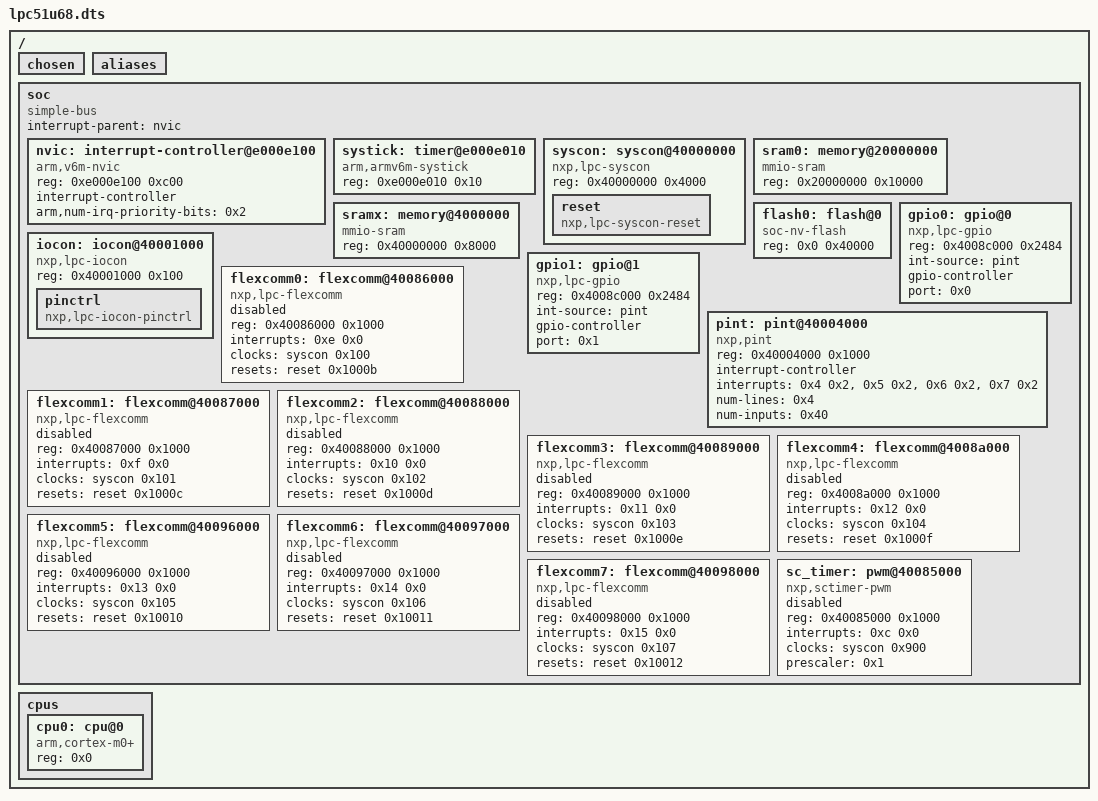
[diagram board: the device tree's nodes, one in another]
/dts-v1/;

/ {
	#address-cells = < 0x1 >;
	#size-cells = < 0x1 >;
	chosen {
	};
	aliases {
	};
	soc {
		#address-cells = < 0x1 >;
		#size-cells = < 0x1 >;
		compatible = "simple-bus";
		interrupt-parent = < &nvic >;
		ranges;
		nvic: interrupt-controller@e000e100 {
			#address-cells = < 0x1 >;
			compatible = "arm,v6m-nvic";
			reg = < 0xe000e100 0xc00 >;
			interrupt-controller;
			#interrupt-cells = < 0x2 >;
			arm,num-irq-priority-bits = < 0x2 >;
			phandle = < 0x1 >;
		};
		systick: timer@e000e010 {
			compatible = "arm,armv6m-systick";
			reg = < 0xe000e010 0x10 >;
		};
		syscon: syscon@40000000 {
			compatible = "nxp,lpc-syscon";
			reg = < 0x40000000 0x4000 >;
			#clock-cells = < 0x1 >;
			phandle = < 0x2 >;
			reset: reset {
				compatible = "nxp,lpc-syscon-reset";
				#reset-cells = < 0x1 >;
				phandle = < 0x3 >;
			};
		};
		sram0: memory@20000000 {
			compatible = "mmio-sram";
			reg = < 0x20000000 0x10000 >;
		};
		sramx: memory@4000000 {
			compatible = "mmio-sram";
			reg = < 0x40000000 0x8000 >;
		};
		flash0: flash@0 {
			compatible = "soc-nv-flash";
			reg = < 0x0 0x40000 >;
		};
		iocon: iocon@40001000 {
			compatible = "nxp,lpc-iocon";
			reg = < 0x40001000 0x100 >;
			#address-cells = < 0x1 >;
			#size-cells = < 0x1 >;
			ranges = < 0x0 0x40001000 0x100 >;
			pinctrl: pinctrl {
				compatible = "nxp,lpc-iocon-pinctrl";
			};
		};
		gpio0: gpio@0 {
			compatible = "nxp,lpc-gpio";
			reg = < 0x4008c000 0x2484 >;
			int-source = "pint";
			gpio-controller;
			#gpio-cells = < 0x2 >;
			port = < 0x0 >;
		};
		gpio1: gpio@1 {
			compatible = "nxp,lpc-gpio";
			reg = < 0x4008c000 0x2484 >;
			int-source = "pint";
			gpio-controller;
			#gpio-cells = < 0x2 >;
			port = < 0x1 >;
		};
		pint: pint@40004000 {
			compatible = "nxp,pint";
			reg = < 0x40004000 0x1000 >;
			interrupt-controller;
			#interrupt-cells = < 0x1 >;
			#address-cells = < 0x0 >;
			interrupts = < 0x4 0x2 >, < 0x5 0x2 >, < 0x6 0x2 >, < 0x7 0x2 >;
			num-lines = < 0x4 >;
			num-inputs = < 0x40 >;
		};
		flexcomm0: flexcomm@40086000 {
			compatible = "nxp,lpc-flexcomm";
			reg = < 0x40086000 0x1000 >;
			interrupts = < 0xe 0x0 >;
			clocks = < &syscon 0x100 >;
			resets = < &reset 0x1000b >;
			status = "disabled";
		};
		flexcomm1: flexcomm@40087000 {
			compatible = "nxp,lpc-flexcomm";
			reg = < 0x40087000 0x1000 >;
			interrupts = < 0xf 0x0 >;
			clocks = < &syscon 0x101 >;
			resets = < &reset 0x1000c >;
			status = "disabled";
		};
		flexcomm2: flexcomm@40088000 {
			compatible = "nxp,lpc-flexcomm";
			reg = < 0x40088000 0x1000 >;
			interrupts = < 0x10 0x0 >;
			clocks = < &syscon 0x102 >;
			resets = < &reset 0x1000d >;
			status = "disabled";
		};
		flexcomm3: flexcomm@40089000 {
			compatible = "nxp,lpc-flexcomm";
			reg = < 0x40089000 0x1000 >;
			interrupts = < 0x11 0x0 >;
			clocks = < &syscon 0x103 >;
			resets = < &reset 0x1000e >;
			status = "disabled";
		};
		flexcomm4: flexcomm@4008a000 {
			compatible = "nxp,lpc-flexcomm";
			reg = < 0x4008a000 0x1000 >;
			interrupts = < 0x12 0x0 >;
			clocks = < &syscon 0x104 >;
			resets = < &reset 0x1000f >;
			status = "disabled";
		};
		flexcomm5: flexcomm@40096000 {
			compatible = "nxp,lpc-flexcomm";
			reg = < 0x40096000 0x1000 >;
			interrupts = < 0x13 0x0 >;
			clocks = < &syscon 0x105 >;
			resets = < &reset 0x10010 >;
			status = "disabled";
		};
		flexcomm6: flexcomm@40097000 {
			compatible = "nxp,lpc-flexcomm";
			reg = < 0x40097000 0x1000 >;
			interrupts = < 0x14 0x0 >;
			clocks = < &syscon 0x106 >;
			resets = < &reset 0x10011 >;
			status = "disabled";
		};
		flexcomm7: flexcomm@40098000 {
			compatible = "nxp,lpc-flexcomm";
			reg = < 0x40098000 0x1000 >;
			interrupts = < 0x15 0x0 >;
			clocks = < &syscon 0x107 >;
			resets = < &reset 0x10012 >;
			status = "disabled";
		};
		sc_timer: pwm@40085000 {
			compatible = "nxp,sctimer-pwm";
			reg = < 0x40085000 0x1000 >;
			status = "disabled";
			interrupts = < 0xc 0x0 >;
			clocks = < &syscon 0x900 >;
			prescaler = < 0x1 >;
			#pwm-cells = < 0x3 >;
		};
	};
	cpus {
		#address-cells = < 0x1 >;
		#size-cells = < 0x0 >;
		cpu0: cpu@0 {
			compatible = "arm,cortex-m0+";
			reg = < 0x0 >;
		};
	};
};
